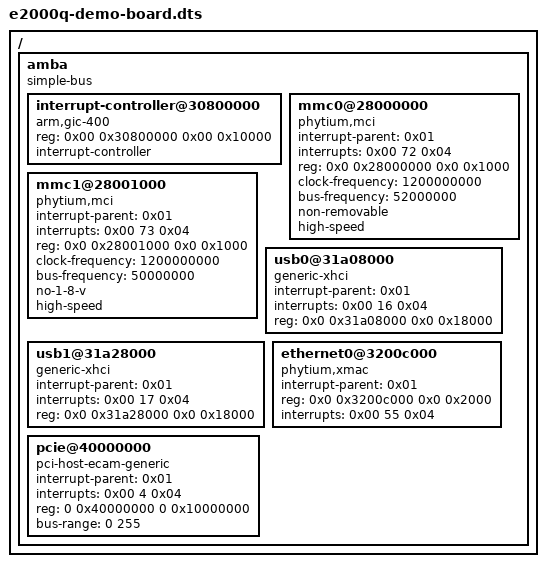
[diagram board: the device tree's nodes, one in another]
/* SPDX-License-Identifier: BSD-2-Clause */

/dts-v1/;

/ {
	#address-cells = <0x02>;
	#size-cells = <0x02>;

	amba {
		compatible = "simple-bus";
		#address-cells = <0x02>;
		#size-cells = <0x02>;
		ranges;

		interrupt-controller@30800000 {
			compatible = "arm,gic-400";
			#address-cells = <0x02>;
			#interrupt-cells = <0x03>;
			reg = <0x00 0x30800000 0x00 0x10000>;
			interrupt-controller;
			phandle = <0x01>;
		};

		mmc0@28000000 {
			compatible = "phytium,mci";
			status = "okay";
			interrupt-parent = <0x01>;
			interrupts = <0x00 72 0x04>;
			reg = <0x0 0x28000000 0x0 0x1000>;
			clock-frequency = <1200000000>;
			bus-frequency = <52000000>;
			non-removable;
			high-speed;
		};

		mmc1@28001000 {
			compatible = "phytium,mci";
			status = "okay";
			interrupt-parent = <0x01>;
			interrupts = <0x00 73 0x04>;
			reg = <0x0 0x28001000 0x0 0x1000>;
			clock-frequency = <1200000000>;
			bus-frequency = <50000000>;
			no-1-8-v;
			high-speed;
		};

		usb0@31a08000 {
			compatible = "generic-xhci";
			status = "okay";
			interrupt-parent = <0x01>;
			/* spi int-id: (48 - 32)  */
			interrupts = <0x00 16 0x04>;
			reg = <0x0 0x31a08000 0x0 0x18000>;
		};

		usb1@31a28000 {
			compatible = "generic-xhci";
			status = "okay";
			interrupt-parent = <0x01>;
			/* spi int-id: (49 - 32)  */
			interrupts = <0x00 17 0x04>;
			reg = <0x0 0x31a28000 0x0 0x18000>;
		};

		ethernet0@3200c000 {
			compatible = "phytium,xmac";
			status = "okay";
			interrupt-parent = <0x01>;
			reg = <0x0 0x3200c000 0x0 0x2000>;
			interrupts = <0x00 55 0x04>;
		};

		pcie@40000000 {
			compatible = "pci-host-ecam-generic";
			status = "okay";
			device_type = "pci";
			#address-cells = <3>;
			#size-cells = <2>;
			#interrupt-cells = <1>;
			interrupt-parent = <0x01>;
			interrupts = <0x00 4 0x04>;
			reg = <0 0x40000000 0 0x10000000>;
			ranges = <0x01000000 0x00 0x00000000 0x0  0x50000000  0x0  0x00f00000
                      0x02000000 0x00 0x58000000 0x0 0x58000000 0x0 0x28000000
                      0x03000000 0x10 0x00000000 0x10 0x00000000 0x10  0x00000000>;
			bus-range = <0 255>;
		};

	};
};
